# PRU_ICSSG2_PR1_MII_RT_PR1_SGMII0_CFG_SGMII0_local register map
Vendor: Texas Instruments
Peripheral module from a debugger description file (folder PG1_0).
Registers are 32-bit, read-write, reset 0x0 unless marked. A register's access mark holds for its fields unless they carry their own. Offsets are as the file gives them; lines under a group give offsets from that group; [hi:lo] are bit positions; {n}, {i} and the like mark numbered series; 'fields as' and 'values as' point back to an identical list; <NAME> marks a mode.

## PRU_ICSSG2_PR1_MII_RT_PR1_SGMII0_CFG_SGMII0
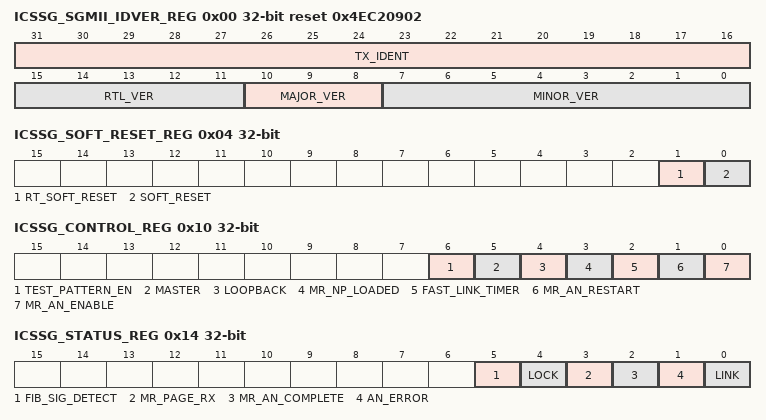
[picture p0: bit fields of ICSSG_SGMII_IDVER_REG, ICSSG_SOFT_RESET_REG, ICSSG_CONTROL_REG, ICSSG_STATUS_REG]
0x00 ICSSG_SGMII_IDVER_REG ro reset 0x4EC20902 — Identification and Version Register SGMII mode is supported only for PRU_ICSSG2 instance.
  [31:16] TX_IDENT — TX Identification Value
  [15:11] RTL_VER — RTL version value
  [10:8] MAJOR_VER — Major Version Value
  [7:0] MINOR_VER — Minor Version Value
0x04 ICSSG_SOFT_RESET_REG — Software Reset Register SGMII mode is supported only for PRU_ICSSG2 instance.
  [1] RT_SOFT_RESET — NOT SUPPORTED
  [0] SOFT_RESET — NOT SUPPORTED
0x10 ICSSG_CONTROL_REG — Control Register SGMII mode is supported only for PRU_ICSSG2 instance.
  [6] TEST_PATTERN_EN — Test Pattern Enable.
  [5] MASTER — Master Mode.
  [4] LOOPBACK — Loopback mode.
  [3] MR_NP_LOADED — Next Page Loaded.
  [2] FAST_LINK_TIMER
  [1] MR_AN_RESTART — Auto.
  [0] MR_AN_ENABLE — Auto.
0x14 ICSSG_STATUS_REG ro (reset mask 0xF) — Status Register SGMII mode is supported only for PRU_ICSSG2 instance.
  [5] FIB_SIG_DETECT — Fiber Signal Detect.
  [4] LOCK
  [3] MR_PAGE_RX — Next Page Received.
  [2] MR_AN_COMPLETE — Auto.
  [1] AN_ERROR — Auto.
  [0] LINK — Link indicator.
0x18 ICSSG_MR_ADV_ABILITY_REG — Advertised Ability Register SGMII mode is supported only for PRU_ICSSG2 instance.
  [15:0] MR_ADV_ABILITY — Advertised Ability.
0x1C ICSSG_MR_NP_TX_REG — Next Page Transmit Register SGMII mode is supported only for PRU_ICSSG2 instance.
  [15:0] MR_NP_TX — Next Page Transmit.
0x20 ICSSG_MR_LP_ADV_ABILITY_REG ro — Link Partner Advertised Ability Register SGMII mode is supported only for PRU_ICSSG2 instance.
  [15:0] MR_LP_ADV_ABILITY — Link Partner Advertised Ability.
0x24 ICSSG_MR_LP_NP_RX_REG ro — Link Partner Next Page Received Register SGMII mode is supported only for PRU_ICSSG2 instance.
  [15:0] MR_LP_NP_RX — Link Partner Next Page Received.
0x30 ICSSG_TX_CFG_REG — SGMII mode is supported only for PRU_ICSSG2 instance.
  [31:0] TX_CFG — Transmit configuration register output
0x34 ICSSG_RX_CFG_REG — SGMII mode is supported only for PRU_ICSSG2 instance.
  [31:0] RX_CFG — Receive configuration register output
0x38 ICSSG_AUX_CFG_REG — SGMII mode is supported only for PRU_ICSSG2 instance.
  [31:0] AUX_CFG — Auxiliary configuration register output
0x40 ICSSG_DIAG_CLEAR_REG — Diagnostics Clear Register SGMII mode is supported only for PRU_ICSSG2 instance.
  [0] DIAG_CLEAR — Diagnostics Clear.
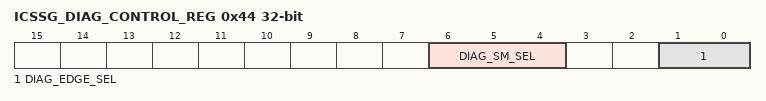
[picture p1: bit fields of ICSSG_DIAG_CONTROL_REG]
0x44 ICSSG_DIAG_CONTROL_REG — Diagnostics Control Register SGMII mode is supported only for PRU_ICSSG2 instance.
  [6:4] DIAG_SM_SEL — Diagnostic Select.
  [1:0] DIAG_EDGE_SEL — Diagnostis Hold Signals Edge Select
0x48 ICSSG_DIAG_STATUS_REG ro — Diagnostics Status Register SGMII mode is supported only for PRU_ICSSG2 instance.
  [15:0] DIAG_STATUS — Diagnostics Status
